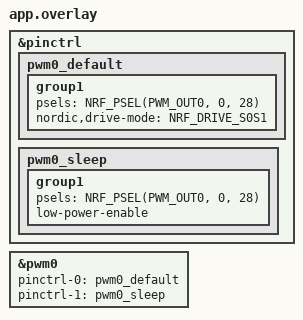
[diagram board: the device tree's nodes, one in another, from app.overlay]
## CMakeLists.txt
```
cmake_minimum_required(VERSION 3.20.0)
find_package(Zephyr REQUIRED HINTS $ENV{ZEPHYR_BASE})

project(blinky_the_second)

target_sources(app PRIVATE
    src/main.c
    src/toggle_led_thread.c
    src/button_interrupt_controlled_led.c
    src/led_utils.c
    src/led_shell_cmd_control.c
    src/bluetooth_service.c
    src/pwm_controller.c
)
```

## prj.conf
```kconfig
# Enable GPIO and basic console
CONFIG_GPIO=y
CONFIG_STDOUT_CONSOLE=y

# Enable PWM
CONFIG_PWM=y


# Enable UART1 and set as console/shell
CONFIG_UART_CONSOLE=y

# Enable Zephyr shell on UART1
CONFIG_SHELL=y
CONFIG_SHELL_BACKEND_SERIAL=y
CONFIG_SHELL_PROMPT_UART="shell> "


CONFIG_BT=y
CONFIG_BT_PERIPHERAL=y
CONFIG_BT_DEVICE_NAME="RadioManBluetoothDevice"
CONFIG_BT_MAX_CONN=1
CONFIG_BT_MAX_PAIRED=1

# Enable the NUS service
CONFIG_BT_NUS=y

# Enable bonding
CONFIG_BT_SETTINGS=y
CONFIG_FLASH=y
CONFIG_FLASH_PAGE_LAYOUT=y
CONFIG_FLASH_MAP=y
```

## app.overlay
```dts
/*
 * Hardware PWM overlay for nRF5340dk
 * PWM0 on P0.28 (LED1) - confirmed working
 */

&pinctrl {
    pwm0_default: pwm0_default {
        group1 {
            psels = <NRF_PSEL(PWM_OUT0, 0, 28)>;
            nordic,drive-mode = <NRF_DRIVE_S0S1>;
        };
    };

    pwm0_sleep: pwm0_sleep {
        group1 {
            psels = <NRF_PSEL(PWM_OUT0, 0, 28)>;
            low-power-enable;
        };
    };
};

&pwm0 {
    status = "okay";
    pinctrl-0 = <&pwm0_default>;
    pinctrl-1 = <&pwm0_sleep>;
    pinctrl-names = "default", "sleep";
};
```

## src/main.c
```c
#include <zephyr/kernel.h>

#include <zephyr/drivers/gpio.h>
#include "toggle_led_thread.h"
#include "led_utils.h"
#include "button_interrupt_controlled_led.h"
#include "led_shell_cmd_control.h"
#include "bluetooth_service.h"
#include "pwm_controller.h"
#include <stdlib.h>
#include <string.h>

/* 1000 msec = 1 sec */
#define SLEEP_TIME_MS   1000
#define FAST_TOGGLE_MS  10   // 10ms = 50Hz toggle rate

// BLE data handler for PWM control
static void handle_ble_data(const uint8_t *data, uint16_t len)
{
    // Convert received data to PWM value
    if (len == 0) {
        return;
    }
    
    uint16_t pwm_value;
    
    // Check if data looks like ASCII digits
    bool is_ascii = true;
    for (int i = 0; i < len; i++) {
        if (data[i] < '0' || data[i] > '9') {
            is_ascii = false;
            break;
        }
    }
    
    if (is_ascii && len > 0) {
        char temp_str[16];
        int copy_len = (len < 15) ? len : 15;
        memcpy(temp_str, data, copy_len);
        temp_str[copy_len] = '\0';
        int parsed_value = atoi(temp_str);
        if (parsed_value < 0) parsed_value = 0;
        if (parsed_value > 1000) parsed_value = 1000;
        pwm_value = (uint16_t)parsed_value;
    } else if (len == 1) {
        pwm_value = data[0];
    } else {
        pwm_value = data[0];
    }

    int ret = set_pwm_duty_cycle(pwm_value);
    if (ret != 0) {
        printk("PWM set err=%d\n", ret);
    }
}


static struct gpio_dt_spec led_4 = GPIO_DT_SPEC_GET(DT_ALIAS(led3), gpios);

void main(void)
{
    int ret;

    // Optional: configure your LEDs as before
    // LED1 (P0.28) is now controlled by hardware PWM - disable GPIO toggle
    // static const struct gpio_dt_spec led_1 = GPIO_DT_SPEC_GET(DT_ALIAS(led0), gpios);
    // ret = configure_led_pin(&led_1);
    // if (ret < 0) {
    //     printk("Failed to configure LED1\n");
    // }
    // init_toggle_led_thread(&led_1);

    static const struct gpio_dt_spec led_2 = GPIO_DT_SPEC_GET(DT_ALIAS(led1), gpios);
    ret = configure_led_pin(&led_2);
    if (ret < 0) {
        printk("Failed to configure LED2\n");
    }
    init_button_interrupt_led(&led_2);

    static const struct gpio_dt_spec led_3 = GPIO_DT_SPEC_GET(DT_ALIAS(led2), gpios);
    ret = configure_led_pin(&led_3);
    if (ret < 0) {
        printk("Failed to configure LED3\n");
    }
    init_led_shell_cmd_control(&led_3);

    // Initialize Hardware PWM controller
    ret = init_pwm_controller();
    if (ret < 0) {
        printk("Failed to initialize Hardware PWM controller\n");
        return;
    }

    // Initialize Bluetooth service with LED4 as connection status indicator
    ret = init_bluetooth_service(&led_4);
    if (ret < 0) {
        printk("Failed to initialize Bluetooth service\n");
        return;
    }
    
    // Set up BLE data callback for Hardware PWM control
    set_ble_data_callback(handle_ble_data);

    // Suppress informational banners to keep output minimal.
    
    // Start Hardware PWM with 25% duty cycle
    set_pwm_duty_cycle(64);
    
    while (1) {
        k_msleep(SLEEP_TIME_MS);
    }
}
```

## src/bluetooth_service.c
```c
#include "bluetooth_service.h"
#include "led_utils.h"

#include <zephyr/kernel.h>
#include <zephyr/drivers/gpio.h>
#include <zephyr/bluetooth/bluetooth.h>
#include <zephyr/bluetooth/uuid.h>
#include <zephyr/bluetooth/gatt.h>
#include <zephyr/bluetooth/hci.h>
#include <bluetooth/services/nus.h>

// (Debug logging removed; keep file minimal)

// Static variables for Bluetooth service
static const struct gpio_dt_spec *status_led = NULL;
static ble_data_callback_t data_callback = NULL;

// (Disconnect reason decoding removed for minimal output)

static void connected(struct bt_conn *conn, uint8_t err)
{
    char addr[BT_ADDR_LE_STR_LEN];
    bt_addr_le_to_str(bt_conn_get_dst(conn), addr, sizeof(addr));
    if (err) {
        printk("BLE conn fail err=%u\n", err);
        return;
    }

    if (status_led) {
        gpio_pin_set_dt(status_led, 1); // Turn on LED4
    }

    // Minimal: no connection detail print
}

static void disconnected(struct bt_conn *conn, uint8_t reason)
{
    char addr[BT_ADDR_LE_STR_LEN];
    bt_addr_le_to_str(bt_conn_get_dst(conn), addr, sizeof(addr));
    if (status_led) {
        gpio_pin_set_dt(status_led, 0); // Turn off LED4
    }
    // Minimal: no disconnect reason print
}

BT_CONN_CB_DEFINE(conn_callbacks) = {
    .connected = connected,
    .disconnected = disconnected,
};

static void bt_receive_cb(struct bt_conn *conn, const uint8_t *const data, uint16_t len)
{
    // Print only the received payload (raw line) for application parsing
    printk("%.*s\n", len, data);
    
    // Call the registered callback if available
    if (data_callback) {
        data_callback(data, len);
    }
}

static struct bt_nus_cb nus_cb = {
    .received = bt_receive_cb,
};

int init_bluetooth_service(const struct gpio_dt_spec *led)
{
    int ret;
    
    // Store the status LED reference
    status_led = led;
    
    // Configure the status LED and set initial state to OFF (not connected)
    if (status_led) {
        ret = configure_led_pin(status_led);
        if (ret < 0) {
            printk("BLE LED cfg err=%d\n", ret);
            return ret;
        }
        // Ensure LED starts in OFF state (not connected)
        gpio_pin_set_dt(status_led, 0);
    }
    
    // Enable Bluetooth
    ret = bt_enable(NULL);
    if (ret) {
        printk("BLE init err=%d\n", ret);
        return ret;
    }

    // Initialize Nordic UART Service
    ret = bt_nus_init(&nus_cb);
    if (ret) {
        printk("NUS init err=%d\n", ret);
        return ret;
    }

    // Start advertising
    ret = bt_le_adv_start(BT_LE_ADV_CONN_NAME, NULL, 0, NULL, 0);
    if (ret) {
        printk("Adv start err=%d\n", ret);
        return ret;
    }
    
    return 0;
}

void set_ble_data_callback(ble_data_callback_t callback)
{
    data_callback = callback;
}
```

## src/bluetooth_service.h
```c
#ifndef BLUETOOTH_SERVICE_H
#define BLUETOOTH_SERVICE_H

#include <zephyr/drivers/gpio.h>
#include <stdint.h>

/**
 * @brief Callback function type for BLE data reception
 * 
 * @param data Pointer to received data
 * @param len Length of received data
 */
typedef void (*ble_data_callback_t)(const uint8_t *data, uint16_t len);

/**
 * @brief Initialize the Bluetooth service
 * 
 * This function initializes Bluetooth, sets up the Nordic UART Service (NUS),
 * starts advertising, and configures the connection status LED.
 * 
 * @param status_led Pointer to GPIO spec for the connection status LED
 * @return int 0 on success, negative error code on failure
 */
int init_bluetooth_service(const struct gpio_dt_spec *status_led);

/**
 * @brief Set callback function for BLE data reception
 * 
 * @param callback Function to call when BLE data is received
 */
void set_ble_data_callback(ble_data_callback_t callback);

#endif // BLUETOOTH_SERVICE_H
```

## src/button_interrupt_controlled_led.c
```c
#include <zephyr/kernel.h>
#include <zephyr/drivers/gpio.h>
#include "button_interrupt_controlled_led.h"
#include "led_utils.h"


#define SW0_NODE DT_ALIAS(sw0)
const struct gpio_dt_spec sw_0 = GPIO_DT_SPEC_GET(SW0_NODE, gpios);

static const struct gpio_dt_spec *_led = NULL;

//--- Private Function Prototype --------------------------------
void _configure_button_interrupt(void);

//--- Public Function Definition -------------------------------
void init_button_interrupt_led(const struct gpio_dt_spec *led) {
    _led = led;
    _configure_button_interrupt();
}

void _button_pressed_isr(const struct device *dev, struct gpio_callback *cb, uint32_t pins)
{
    if (_led) {
        gpio_pin_toggle_dt(_led);
    }
}

static struct gpio_callback button_cb_data;

void _configure_button_interrupt(void)
{
    int ret;

    ret = gpio_pin_configure_dt(&sw_0, GPIO_INPUT);
    if (ret != 0) {
        printf("Error %d: failed to configure button pin %s\n", ret, sw_0.port->name);
        return;
    }

    ret = gpio_pin_interrupt_configure_dt(&sw_0, GPIO_INT_EDGE_TO_ACTIVE);
    if (ret != 0) {
        printf("Error %d: failed to configure interrupt on %s pin %d\n", ret, sw_0.port->name, sw_0.pin);
        return;
    }

    gpio_init_callback(&button_cb_data, _button_pressed_isr, BIT(sw_0.pin));
    gpio_add_callback(sw_0.port, &button_cb_data);
    printf("Set up button at %s pin %d\n", sw_0.port->name, sw_0.pin);
}
```

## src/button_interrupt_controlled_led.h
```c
#ifndef BUTTON_INTERRUPT_CONTROLLED_LED_H
#define BUTTON_INTERRUPT_CONTROLLED_LED_H

void init_button_interrupt_led(const struct gpio_dt_spec *led);

#endif // BUTTON_INTERRUPT_CONTROLLED_LED_H
```

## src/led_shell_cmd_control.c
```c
#include <zephyr/kernel.h>
#include <zephyr/drivers/gpio.h>
#include <zephyr/shell/shell.h>
#include "led_shell_cmd_control.h"


static const struct gpio_dt_spec *_led = NULL;

void init_led_shell_cmd_control(const struct gpio_dt_spec *led) {
    _led = led;
}

static int cmd_control_led(const struct shell *shell, size_t argc, char **argv)
{
    if (argc != 2) {
        shell_print(shell, "Usage: led <on|off>");
        return -EINVAL;
    }

    if (!_led) {
        shell_print(shell, "LED not initialized");
        return -ENODEV;
    }
    if (strcmp(argv[1], "on") == 0) {
        gpio_pin_set_dt(_led, 1);
        shell_print(shell, "LED turned on");
    } else if (strcmp(argv[1], "off") == 0) {
        gpio_pin_set_dt(_led, 0);
        shell_print(shell, "LED turned off");
    } else {
        shell_print(shell, "Invalid argument: %s", argv[1]);
        return -EINVAL;
    }

    return 0;
}

SHELL_CMD_REGISTER(led, NULL, "Control LED (on/off)", cmd_control_led);
```

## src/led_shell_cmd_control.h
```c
#ifndef LED_SHELL_CMD_CONTROL_H
#define LED_SHELL_CMD_CONTROL_H

void init_led_shell_cmd_control(const struct gpio_dt_spec *led);

#endif // LED_SHELL_CMD_CONTROL_H
```

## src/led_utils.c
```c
#include "led_utils.h"
#include <zephyr/kernel.h>

int configure_led_pin(const struct gpio_dt_spec *led)
{
    if (!device_is_ready(led->port)) {
        printk("LED device not ready\n");
        return -ENODEV;
    }
    int ret = gpio_pin_configure_dt(led, GPIO_OUTPUT_ACTIVE);
    if (ret < 0) {
        printk("Failed to configure LED pin\n");
    }
    return ret;
}
```

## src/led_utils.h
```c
#ifndef LED_UTILS_H
#define LED_UTILS_H

#include <zephyr/drivers/gpio.h>

int configure_led_pin(const struct gpio_dt_spec *led);

#endif // LED_UTILS_H
```

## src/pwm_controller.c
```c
#include "pwm_controller.h"

#include <zephyr/kernel.h>
#include <zephyr/drivers/pwm.h>
#include <zephyr/device.h>

// RC Servo PWM configuration
#define PWM_PERIOD_NS 20000000U   // 20ms period (50Hz) - RC servo standard
#define PWM_MIN_PULSE_NS 1000000U // 1ms minimum pulse (0%)
#define PWM_MAX_PULSE_NS 2000000U // 2ms maximum pulse (100%)
#define PWM_CENTER_PULSE_NS 1500000U // 1.5ms center pulse (50%)

// PWM device tree specification - get first available PWM device
static const struct device *pwm_dev;
static const uint32_t pwm_channel = 0;

// Static variables
static uint16_t current_position = 500; // Center position (1.5ms)
static bool pwm_enabled = false;

int init_pwm_controller(void)
{
    // Try to get PWM2 device first
    pwm_dev = DEVICE_DT_GET_OR_NULL(DT_NODELABEL(pwm2));
    if (!pwm_dev) {
        pwm_dev = DEVICE_DT_GET_OR_NULL(DT_NODELABEL(pwm1));
        if (!pwm_dev) {
            pwm_dev = DEVICE_DT_GET_OR_NULL(DT_NODELABEL(pwm0));
            if (!pwm_dev) {
                printk("Error: No PWM device available\n");
                return -ENODEV;
            }
        }
    }

    // Check if PWM device is ready
    if (!device_is_ready(pwm_dev)) {
        printk("Error: PWM device not ready\n");
        return -ENODEV;
    }
    // Start with center position (50% = 1.5ms pulse)
    int ret = pwm_set(pwm_dev, pwm_channel, PWM_PERIOD_NS, PWM_CENTER_PULSE_NS, PWM_POLARITY_NORMAL);
    if (ret < 0) {
        printk("Error setting PWM: %d\n", ret);
        return ret;
    }
    current_position = 500; // Center position = 500/1000
    pwm_enabled = true;
    
    return 0;
}

int set_pwm_duty_cycle(uint16_t position)
{
    if (!pwm_enabled || !pwm_dev) {
        printk("PWM not initialized\n");
        return -ENODEV;
    }
    
    // Convert 0-1000 to RC servo pulse width (1ms to 2ms)
    uint32_t pulse_ns = PWM_MIN_PULSE_NS + ((PWM_MAX_PULSE_NS - PWM_MIN_PULSE_NS) * position) / 1000;
    
    int ret = pwm_set(pwm_dev, pwm_channel, PWM_PERIOD_NS, pulse_ns, PWM_POLARITY_NORMAL);
    if (ret < 0) {
        printk("Error setting PWM duty cycle: %d\n", ret);
        return ret;
    }
    
    current_position = position;
    return 0;
}

uint16_t get_pwm_duty_cycle(void)
{
    return current_position;
}

int enable_pwm(bool enable)
{
    if (enable && !pwm_enabled) {
        // Enable with current duty cycle
        return set_pwm_duty_cycle(current_position);
    } else if (!enable && pwm_enabled) {
        // Disable by setting to 0
        uint16_t saved_position = current_position;
        int ret = set_pwm_duty_cycle(0);
        current_position = saved_position;  // Restore for next enable
        pwm_enabled = false;
        return ret;
    }
    
    return 0;  // Already in desired state
}
```

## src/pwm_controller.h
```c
#ifndef PWM_CONTROLLER_H
#define PWM_CONTROLLER_H

#include <stdint.h>
#include <stdbool.h>

/**
 * @brief RC Servo PWM Controller Module
 * 
 * This module provides RC servo control via hardware PWM on P0.28.
 * Generates standard RC servo signals: 50Hz (20ms period), 1-2ms pulse width.
 * Input range: 0-1000 (0 = 1ms, 500 = 1.5ms, 1000 = 2ms)
 */

/**
 * @brief Initialize the PWM controller
 * 
 * Sets up the PWM device and configures the output pin.
 * 
 * @return int 0 on success, negative error code on failure
 */
int init_pwm_controller(void);

/**
 * @brief Set RC servo position
 * 
 * @param position Servo position (0-1000, where 0=1ms, 500=1.5ms, 1000=2ms)
 * @return int 0 on success, negative error code on failure
 */
int set_pwm_duty_cycle(uint16_t position);

/**
 * @brief Get current servo position
 * 
 * @return uint16_t Current position (0-1000)
 */
uint16_t get_pwm_duty_cycle(void);

/**
 * @brief Enable/disable PWM output
 * 
 * @param enable true to enable PWM, false to disable
 * @return int 0 on success, negative error code on failure
 */
int enable_pwm(bool enable);

#endif // PWM_CONTROLLER_H
```

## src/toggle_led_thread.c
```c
#include <zephyr/kernel.h>
#include <zephyr/drivers/gpio.h>
#include "toggle_led_thread.h"
#include "led_utils.h"

#define SLEEP_TIME_MS 1000

static const struct gpio_dt_spec *_led = NULL;

void init_toggle_led_thread(const struct gpio_dt_spec *led) {
    _led = led;
}

void _toggle_led_thread(void *unused0, void *unused1, void *unused2)
{
    while (1) {
        if (_led) {
            gpio_pin_toggle_dt(_led);
        }
        k_msleep(SLEEP_TIME_MS);
    }
}

K_THREAD_DEFINE(toggle_led_tid, 1024, _toggle_led_thread, NULL, NULL, NULL, 7, 0, 0);
```

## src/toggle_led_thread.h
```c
#ifndef TOGGLE_LED_THREAD_H
#define TOGGLE_LED_THREAD_H

void init_toggle_led_thread(const struct gpio_dt_spec *led);

#endif // TOGGLE_LED_THREAD_H
```
